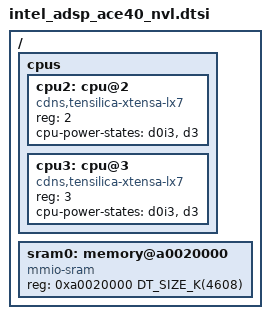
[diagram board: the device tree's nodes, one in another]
/*
 * Copyright (c) 2025 Intel Corporation
 *
 * SPDX-License-Identifier: Apache-2.0
 */

#include <xtensa/intel/intel_adsp_ace40.dtsi>

/ {
	cpus {
		cpu2: cpu@2 {
			compatible = "cdns,tensilica-xtensa-lx7";
			reg = <2>;
			device_type = "cpu";
			cpu-power-states = <&d0i3 &d3>;
		};

		cpu3: cpu@3 {
			compatible = "cdns,tensilica-xtensa-lx7";
			reg = <3>;
			device_type = "cpu";
			cpu-power-states = <&d0i3 &d3>;
		};
	};

	sram0: memory@a0020000 {
		compatible = "mmio-sram";
		reg = <0xa0020000 DT_SIZE_K(4608)>;
		device_type = "memory";
	};
};
